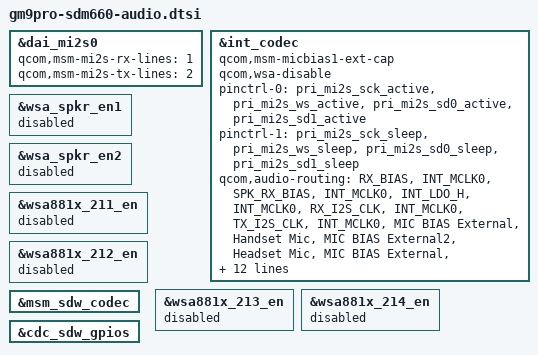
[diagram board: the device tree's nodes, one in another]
&dai_mi2s0 {
	qcom,msm-mi2s-rx-lines = <1>;
	qcom,msm-mi2s-tx-lines = <2>;
};

&int_codec {
	/delete-property/ qcom,msm-micbias2-ext-cap;
	/delete-property/ qcom,us-euro-gpios;
	qcom,msm-micbias1-ext-cap;
	qcom,wsa-disable;
	pinctrl-names = "pri_i2s_active", "pri_i2s_sleep";
	pinctrl-0 = <&pri_mi2s_sck_active &pri_mi2s_ws_active
			&pri_mi2s_sd0_active &pri_mi2s_sd1_active>;
	pinctrl-1 = <&pri_mi2s_sck_sleep &pri_mi2s_ws_sleep
			&pri_mi2s_sd0_sleep &pri_mi2s_sd1_sleep>;
	qcom,audio-routing =
		"RX_BIAS", "INT_MCLK0",
		"SPK_RX_BIAS", "INT_MCLK0",
		"INT_LDO_H", "INT_MCLK0",
		"RX_I2S_CLK", "INT_MCLK0",
		"TX_I2S_CLK", "INT_MCLK0",
		"MIC BIAS External", "Handset Mic",
		"MIC BIAS External2", "Headset Mic",
		"MIC BIAS External", "Secondary Mic",
		"AMIC1", "MIC BIAS External",
		"AMIC2", "MIC BIAS External2",
		"AMIC3", "MIC BIAS External",
		"DMIC1", "MIC BIAS External",
		"MIC BIAS External", "Digital Mic1",
		"DMIC2", "MIC BIAS External",
		"MIC BIAS External", "Digital Mic2",
		"DMIC3", "MIC BIAS External",
		"MIC BIAS External", "Digital Mic3",
		"DMIC4", "MIC BIAS External",
		"MIC BIAS External", "Digital Mic4",
		"PDM_IN_RX1", "PDM_OUT_RX1",
		"PDM_IN_RX2", "PDM_OUT_RX2",
		"PDM_IN_RX3", "PDM_OUT_RX3",
		"ADC1_IN", "ADC1_OUT",
		"ADC2_IN", "ADC2_OUT",
		"ADC3_IN", "ADC3_OUT";
};

&wsa_spkr_en1 {
	status = "disabled";
};

&wsa_spkr_en2 {
	status = "disabled";
};

&wsa881x_211_en {
	status = "disabled";
};

&wsa881x_212_en {
	status = "disabled";
};

&wsa881x_213_en {
	status = "disabled";
};

&wsa881x_214_en {
	status = "disabled";
};

&msm_sdw_codec {
	/delete-property/ qcom,cdc-sdw-gpios;
};

&cdc_sdw_gpios {
	/delete-property/ pinctrl-names;
	/delete-property/ pinctrl-0;
	/delete-property/ pinctrl-1;
};
